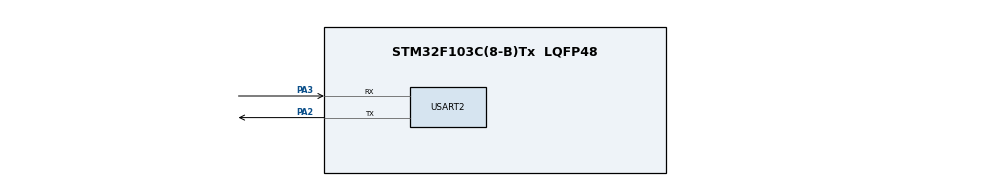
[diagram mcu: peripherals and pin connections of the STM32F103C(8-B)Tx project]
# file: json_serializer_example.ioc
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Mcu.Family=STM32F1
Mcu.Name=STM32F103C(8-B)Tx
Mcu.Package=LQFP48
NVIC.PriorityGroup=NVIC_PRIORITYGROUP_4
NVIC.RCC_IRQn=true\:0\:0\:false\:false\:true\:true\:false\:true
PA2.Mode=Asynchronous
PA2.Signal=USART2_TX
PA3.Mode=Asynchronous
PA3.Signal=USART2_RX
ProjectManager.HeapSize=0x200
ProjectManager.StackSize=0x400
ProjectManager.TargetToolchain=STM32CubeIDE
RCC.APB1Freq_Value=8000000
RCC.APB2Freq_Value=8000000
RCC.USBFreq_Value=8000000
USART2.VirtualMode=VM_ASYNC
VP_SYS_VS_ND.Mode=No_Debug
board=custom

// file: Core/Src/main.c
/* USER CODE BEGIN Header */
/**
  ******************************************************************************
  * @file           : main.c
  * @brief          : Main program body
  ******************************************************************************
  * @attention
  *
  * Copyright (c) 2026 STMicroelectronics.
  * All rights reserved.
  *
  * This software is licensed under terms that can be found in the LICENSE file
  * in the root directory of this software component.
  * If no LICENSE file comes with this software, it is provided AS-IS.
  *
  ******************************************************************************
  */
/* USER CODE END Header */
#include "main.h"

/* USER CODE BEGIN Includes */
#include "json_serializer.h"
#include <string.h>
#include <stdio.h>
/* USER CODE END Includes */

UART_HandleTypeDef huart2;

void SystemClock_Config(void);
static void MX_GPIO_Init(void);
static void MX_USART2_UART_Init(void);
/* USER CODE BEGIN PFP */

/* ============================
 * Sample Data Initialization
 * ============================ */

static void create_sample_data(gateway_data_t *data)
{
    memset(data, 0, sizeof(gateway_data_t));

    /* Gateway metadata */
    strcpy(data->gateway_id, "gateway_1234");
    strcpy(data->date, "1970-01-01");
    strcpy(data->device_type, "stromleser");

    data->interval_minutes = 15;
    data->total_readings   = 1;

    /* Values */
    data->values.device_count = 1;

    device_reading_t *dev = &data->values.readings[0];
    strcpy(dev->media, "water");
    strcpy(dev->meter, "waterstarm");
    strcpy(dev->device_id, "stromleser_50898527");
    strcpy(dev->unit, "m3");

    dev->data_count = 1;

    meter_data_point_t *dp = &dev->data[0];
    strcpy(dp->timestamp, "1970-01-01 00:00");
    strcpy(dp->meter_datetime, "1970-01-01 00:00");
    dp->total_m3 = 107.752f;
    strcpy(dp->status, "OK");
}

/* ============================
 * UART Print Helper
 * ============================ */

static void uart_print(const char *str)
{
    HAL_UART_Transmit(
        &huart2,
        (uint8_t *)str,
        strlen(str),
        HAL_MAX_DELAY
    );
}

/* USER CODE END PFP */

int main(void)
{

  /* Reset of all peripherals, Initializes the Flash interface and the Systick. */
  HAL_Init();

  /* Configure the system clock */
  SystemClock_Config();

  /* Initialize all configured peripherals */
  MX_GPIO_Init();
  MX_USART2_UART_Init();

  /* USER CODE BEGIN 2 */
  uart_print("\r\nJSON Serializer Example\r\n");

  gateway_data_t gateway_data;
  create_sample_data(&gateway_data);

  char json_buffer[512];
  size_t bytes_written = 0;

  json_serializer_status_t status = json_serialize(
      &gateway_data,
      json_buffer,
      sizeof(json_buffer),
      &bytes_written
  );

  if (status == JSON_SERIALIZER_OK)
  {
      uart_print("Serialization successful:\r\n");
      uart_print(json_buffer);
      uart_print("\r\n");
  }
  else
  {
      char err_msg[64];
      snprintf(err_msg, sizeof(err_msg),
               "Serialization failed, error=%d\r\n", status);
      uart_print(err_msg);
  }

  /* USER CODE END 2 */

  /* Infinite loop */
  while (1)
  {

  }
}

void SystemClock_Config(void)
{
  RCC_OscInitTypeDef RCC_OscInitStruct = {0};
  RCC_ClkInitTypeDef RCC_ClkInitStruct = {0};

  /** Initializes the RCC Oscillators according to the specified parameters
  * in the RCC_OscInitTypeDef structure.
  */
  RCC_OscInitStruct.OscillatorType = RCC_OSCILLATORTYPE_HSI;
  RCC_OscInitStruct.HSIState = RCC_HSI_ON;
  RCC_OscInitStruct.HSICalibrationValue = RCC_HSICALIBRATION_DEFAULT;
  RCC_OscInitStruct.PLL.PLLState = RCC_PLL_NONE;
  if (HAL_RCC_OscConfig(&RCC_OscInitStruct) != HAL_OK)
  {
    Error_Handler();
  }

  /** Initializes the CPU, AHB and APB buses clocks
  */
  RCC_ClkInitStruct.ClockType = RCC_CLOCKTYPE_HCLK|RCC_CLOCKTYPE_SYSCLK
                              |RCC_CLOCKTYPE_PCLK1|RCC_CLOCKTYPE_PCLK2;
  RCC_ClkInitStruct.SYSCLKSource = RCC_SYSCLKSOURCE_HSI;
  RCC_ClkInitStruct.AHBCLKDivider = RCC_SYSCLK_DIV1;
  RCC_ClkInitStruct.APB1CLKDivider = RCC_HCLK_DIV1;
  RCC_ClkInitStruct.APB2CLKDivider = RCC_HCLK_DIV1;

  if (HAL_RCC_ClockConfig(&RCC_ClkInitStruct, FLASH_LATENCY_0) != HAL_OK)
  {
    Error_Handler();
  }
}

static void MX_USART2_UART_Init(void)
{

  huart2.Instance = USART2;
  huart2.Init.BaudRate = 115200;
  huart2.Init.WordLength = UART_WORDLENGTH_8B;
  huart2.Init.StopBits = UART_STOPBITS_1;
  huart2.Init.Parity = UART_PARITY_NONE;
  huart2.Init.Mode = UART_MODE_TX_RX;
  huart2.Init.HwFlowCtl = UART_HWCONTROL_NONE;
  huart2.Init.OverSampling = UART_OVERSAMPLING_16;
  if (HAL_UART_Init(&huart2) != HAL_OK)
  {
    Error_Handler();
  }

}

static void MX_GPIO_Init(void)
{

  /* GPIO Ports Clock Enable */
  __HAL_RCC_GPIOA_CLK_ENABLE();

}

void Error_Handler(void)
{
  __disable_irq();
  while (1)
  {
  }
}
